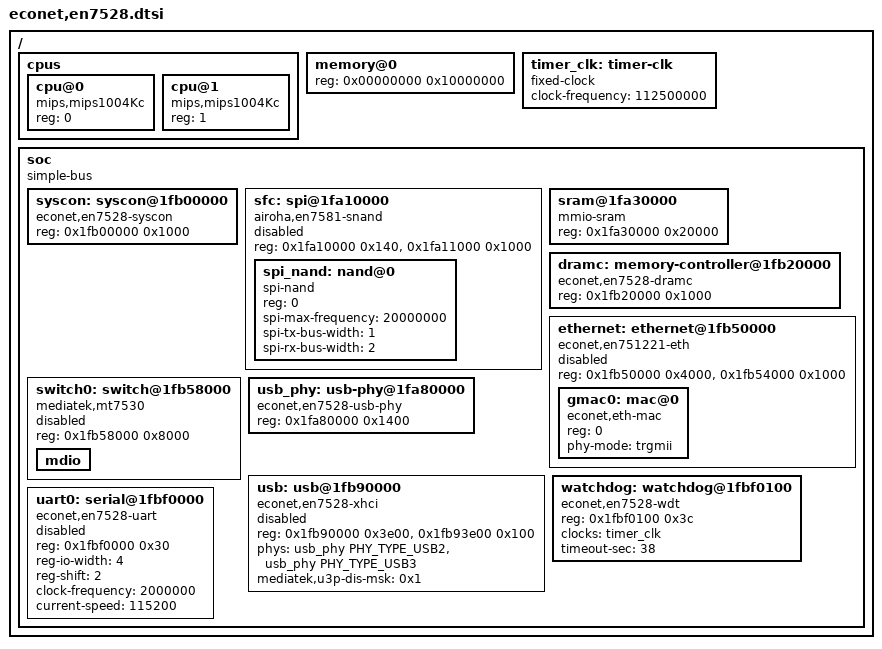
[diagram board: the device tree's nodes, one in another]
// SPDX-License-Identifier: GPL-2.0+
/* EcoNet/Airoha EN7528 (MIPS 1004Kc, little-endian) */

#include <dt-bindings/phy/phy.h>

/ {
	#address-cells = <1>;
	#size-cells = <1>;

	cpus {
		#address-cells = <1>;
		#size-cells = <0>;

		cpu@0 {
			compatible = "mips,mips1004Kc";
			device_type = "cpu";
			reg = <0>;
		};

		cpu@1 {
			compatible = "mips,mips1004Kc";
			device_type = "cpu";
			reg = <1>;
		};
	};

	memory@0 {
		device_type = "memory";
		/* Capped below the 0x1fxxxxxx MMIO island; DDR stage
		 * publishes the true size at runtime (dram_init). */
		reg = <0x00000000 0x10000000>;
	};

	/* 定时器块的计数时钟（GS2107 实测 112.5 MHz：Linux en7528_wdt 开 timer 5 不开复位，110.07 ms 计 12,382,778） */
	timer_clk: timer-clk {
		compatible = "fixed-clock";
		#clock-cells = <0>;
		clock-frequency = <112500000>;
	};

	soc {
		compatible = "simple-bus";
		#address-cells = <1>;
		#size-cells = <1>;
		ranges;

		syscon: syscon@1fb00000 {
			compatible = "econet,en7528-syscon", "syscon";
			reg = <0x1fb00000 0x1000>;
		};

		sfc: spi@1fa10000 {
			compatible = "airoha,en7581-snand";
			reg = <0x1fa10000 0x140>,
			      <0x1fa11000 0x1000>;	/* NFI: driver uses up to 0x55c;
							 * U-Boot regmap range-checks (Linux
							 * gets a full page from ioremap). */
			#address-cells = <1>;
			#size-cells = <0>;
			status = "disabled";

			spi_nand: nand@0 {
				compatible = "spi-nand";
				reg = <0>;
				spi-max-frequency = <20000000>;
				spi-tx-bus-width = <1>;
				spi-rx-bus-width = <2>;
			};
		};

		sram@1fa30000 {
			compatible = "mmio-sram";
			reg = <0x1fa30000 0x20000>;
		};

		dramc: memory-controller@1fb20000 {
			compatible = "econet,en7528-dramc";
			reg = <0x1fb20000 0x1000>;
		};

		/*
		 * EN7528 Ethernet = same EN751221-family FE/QDMA as the EN7512,
		 * feeding an MT7530-family DSA switch (GMAC0 -> switch CPU port).
		 * The airoha_eth U-Boot driver binds "econet,en751221-eth" and
		 * self-initializes the "mediatek,mt7530" switch.
		 */
		ethernet: ethernet@1fb50000 {
			compatible = "econet,en751221-eth";
			reg = <0x1fb50000 0x4000>,
			      <0x1fb54000 0x1000>;
			reg-names = "fe", "qdma0";
			#address-cells = <1>;
			#size-cells = <0>;
			status = "disabled";

			gmac0: mac@0 {
				compatible = "econet,eth-mac";
				reg = <0>;
				phy-mode = "trgmii";
			};
		};

		switch0: switch@1fb58000 {
			compatible = "mediatek,mt7530";
			reg = <0x1fb58000 0x8000>;
			status = "disabled";

			/* 内置 GPHY（用户口 1–4 在地址 9–12），经交换芯片的 PHY 间接访问寄存器读写 */
			mdio {
				#address-cells = <1>;
				#size-cells = <0>;
			};
		};

		usb_phy: usb-phy@1fa80000 {
			compatible = "econet,en7528-usb-phy";
			reg = <0x1fa80000 0x1400>;
			#phy-cells = <1>;
		};

		/*
		 * USB 主控是 MediaTek xHCI（与 mt8173 同一 IP），由 xhci-mtk 驱动。"mac" 是 xHCI 寄存器，"ippc" 是紧随其后的 IP 端口控制块，地址与原厂 3.18 内核的 "u3h"/"ippc" 资源及 OpenWrt 的 en7528.dtsi 相同；xhci-mtk 在 probe 时经 IPPC 软复位整个 IP，再给主控和各口上电。与 Linux 的节点一样不带 clocks。
		 *
		 * U3 口（EN7528 只有一个）用 mediatek,u3p-dis-msk 关掉，只起 USB2：U-Boot 读 U 盘用 HS 就够。要开 U3 时去掉该属性，并按 OpenWrt 的 915 补丁补上 LTSSM 时序参数。
		 */
		usb: usb@1fb90000 {
			compatible = "econet,en7528-xhci", "mediatek,mtk-xhci";
			reg = <0x1fb90000 0x3e00>,
			      <0x1fb93e00 0x100>;
			reg-names = "mac", "ippc";
			phys = <&usb_phy PHY_TYPE_USB2>, <&usb_phy PHY_TYPE_USB3>;
			mediatek,u3p-dis-msk = <0x1>;
			status = "disabled";
		};

		/*
		 * 定时器块（0x1fbf0100）的 timer 5 作看门狗，寄存器模型同 Linux 的 en7528_wdt。SoC 内部的块、不依赖板上接线，
		 * 默认启用；编了 WDT_EN7528 的构建由 WATCHDOG_AUTOSTART 从 board_r 起开着它、跳内核不停。超时取硬件上限：
		 * 32 位重装值在 112.5 MHz 下约 38.2 s，从 bootm 最后一次喂狗到内核接手有足够余量。
		 */
		watchdog: watchdog@1fbf0100 {
			compatible = "econet,en7528-wdt";
			reg = <0x1fbf0100 0x3c>;
			clocks = <&timer_clk>;
			timeout-sec = <38>;
		};

		uart0: serial@1fbf0000 {
			compatible = "econet,en7528-uart";
			reg = <0x1fbf0000 0x30>;
			reg-io-width = <4>;
			reg-shift = <2>;
			clock-frequency = <2000000>;
			current-speed = <115200>;
			status = "disabled";
		};
	};
};
